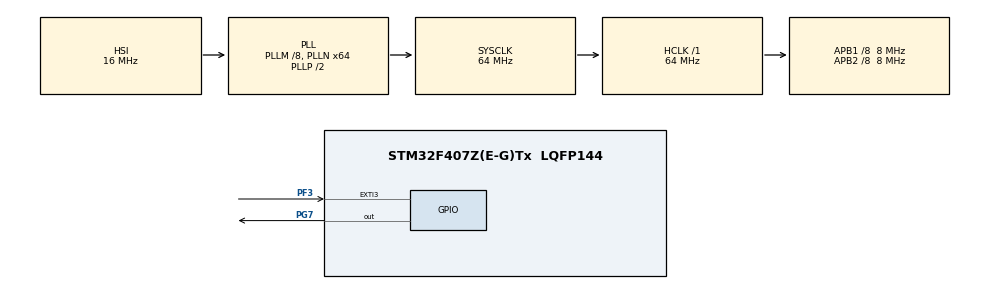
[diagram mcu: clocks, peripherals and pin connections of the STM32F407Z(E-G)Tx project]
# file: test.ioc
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Mcu.Family=STM32F4
Mcu.Name=STM32F407Z(E-G)Tx
Mcu.Package=LQFP144
NVIC.EXTI3_IRQn=true\:0\:0\:false\:false\:true\:true\:true\:true
NVIC.PriorityGroup=NVIC_PRIORITYGROUP_4
NVIC.TIM6_DAC_IRQn=true\:0\:0\:false\:false\:true\:true\:true\:true
PF3.Signal=GPXTI3
PG7.Signal=GPIO_Output
ProjectManager.HeapSize=0x200
ProjectManager.StackSize=0x400
ProjectManager.TargetToolchain=STM32CubeIDE
RCC.48MHZClocksFreq_Value=32000000
RCC.AHBFreq_Value=64000000
RCC.APB1CLKDivider=RCC_HCLK_DIV8
RCC.APB1Freq_Value=8000000
RCC.APB1TimFreq_Value=16000000
RCC.APB2CLKDivider=RCC_HCLK_DIV8
RCC.APB2Freq_Value=8000000
RCC.APB2TimFreq_Value=16000000
RCC.CortexFreq_Value=64000000
RCC.HCLKFreq_Value=64000000
RCC.HSE_VALUE=25000000
RCC.HSI_VALUE=16000000
RCC.LSE_VALUE=32768
RCC.PLLM=8
RCC.PLLN=64
RCC.SYSCLKFreq_VALUE=64000000
RCC.SYSCLKSource=RCC_SYSCLKSOURCE_PLLCLK
RCC.VCOOutputFreq_Value=128000000
TIM6.Period=65535
TIM6.Prescaler=15999
VP_TIM6_VS_ClockSourceINT.Mode=Enable_Timer
board=custom

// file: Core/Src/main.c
/* USER CODE BEGIN Header */
/**
  ******************************************************************************
  * @file           : main.c
  * @brief          : Main program body
  ******************************************************************************
  * @attention
  *
  * Copyright (c) 2023 STMicroelectronics.
  * All rights reserved.
  *
  * This software is licensed under terms that can be found in the LICENSE file
  * in the root directory of this software component.
  * If no LICENSE file comes with this software, it is provided AS-IS.
  *
  ******************************************************************************
  */
/* USER CODE END Header */
#include "main.h"

TIM_HandleTypeDef htim6;

/* USER CODE BEGIN PV */
int delay_reference=1000;
int delay;
int number_pressed=1;
int statuse;  // 0: idle 1: first  2: second
int t6;

/* USER CODE END PV */

void SystemClock_Config(void);
static void MX_GPIO_Init(void);
static void MX_TIM6_Init(void);

int main(void)
{
  /* USER CODE BEGIN 1 */
	delay=delay_reference;

	// External Interrupt ISR Handler CallBackFun

  /* USER CODE END 1 */

  /* MCU Configuration--------------------------------------------------------*/

  /* Reset of all peripherals, Initializes the Flash interface and the Systick. */
  HAL_Init();

  /* Configure the system clock */
  SystemClock_Config();

  /* Initialize all configured peripherals */
  MX_GPIO_Init();
  MX_TIM6_Init();

  /* Infinite loop */
  while (1)
  {

  }
}

void SystemClock_Config(void)
{
  RCC_OscInitTypeDef RCC_OscInitStruct = {0};
  RCC_ClkInitTypeDef RCC_ClkInitStruct = {0};

  /** Configure the main internal regulator output voltage
  */
  __HAL_RCC_PWR_CLK_ENABLE();
  __HAL_PWR_VOLTAGESCALING_CONFIG(PWR_REGULATOR_VOLTAGE_SCALE1);

  /** Initializes the RCC Oscillators according to the specified parameters
  * in the RCC_OscInitTypeDef structure.
  */
  RCC_OscInitStruct.OscillatorType = RCC_OSCILLATORTYPE_HSI;
  RCC_OscInitStruct.HSIState = RCC_HSI_ON;
  RCC_OscInitStruct.HSICalibrationValue = RCC_HSICALIBRATION_DEFAULT;
  RCC_OscInitStruct.PLL.PLLState = RCC_PLL_ON;
  RCC_OscInitStruct.PLL.PLLSource = RCC_PLLSOURCE_HSI;
  RCC_OscInitStruct.PLL.PLLM = 8;
  RCC_OscInitStruct.PLL.PLLN = 64;
  RCC_OscInitStruct.PLL.PLLP = RCC_PLLP_DIV2;
  RCC_OscInitStruct.PLL.PLLQ = 4;
  if (HAL_RCC_OscConfig(&RCC_OscInitStruct) != HAL_OK)
  {
    Error_Handler();
  }

  /** Initializes the CPU, AHB and APB buses clocks
  */
  RCC_ClkInitStruct.ClockType = RCC_CLOCKTYPE_HCLK|RCC_CLOCKTYPE_SYSCLK
                              |RCC_CLOCKTYPE_PCLK1|RCC_CLOCKTYPE_PCLK2;
  RCC_ClkInitStruct.SYSCLKSource = RCC_SYSCLKSOURCE_PLLCLK;
  RCC_ClkInitStruct.AHBCLKDivider = RCC_SYSCLK_DIV1;
  RCC_ClkInitStruct.APB1CLKDivider = RCC_HCLK_DIV8;
  RCC_ClkInitStruct.APB2CLKDivider = RCC_HCLK_DIV8;

  if (HAL_RCC_ClockConfig(&RCC_ClkInitStruct, FLASH_LATENCY_2) != HAL_OK)
  {
    Error_Handler();
  }
}

static void MX_TIM6_Init(void)
{

  TIM_MasterConfigTypeDef sMasterConfig = {0};

  htim6.Instance = TIM6;
  htim6.Init.Prescaler = 15999;
  htim6.Init.CounterMode = TIM_COUNTERMODE_UP;
  htim6.Init.Period = 65535;
  htim6.Init.AutoReloadPreload = TIM_AUTORELOAD_PRELOAD_DISABLE;
  if (HAL_TIM_Base_Init(&htim6) != HAL_OK)
  {
    Error_Handler();
  }
  sMasterConfig.MasterOutputTrigger = TIM_TRGO_RESET;
  sMasterConfig.MasterSlaveMode = TIM_MASTERSLAVEMODE_DISABLE;
  if (HAL_TIMEx_MasterConfigSynchronization(&htim6, &sMasterConfig) != HAL_OK)
  {
    Error_Handler();
  }

}

static void MX_GPIO_Init(void)
{
  GPIO_InitTypeDef GPIO_InitStruct = {0};

  /* GPIO Ports Clock Enable */
  __HAL_RCC_GPIOF_CLK_ENABLE();
  __HAL_RCC_GPIOG_CLK_ENABLE();

  /*Configure GPIO pin Output Level */
  HAL_GPIO_WritePin(GPIOG, GPIO_PIN_7, GPIO_PIN_RESET);

  /*Configure GPIO pin : PF3 */
  GPIO_InitStruct.Pin = GPIO_PIN_3;
  GPIO_InitStruct.Mode = GPIO_MODE_IT_RISING;
  GPIO_InitStruct.Pull = GPIO_NOPULL;
  HAL_GPIO_Init(GPIOF, &GPIO_InitStruct);

  /*Configure GPIO pin : PG7 */
  GPIO_InitStruct.Pin = GPIO_PIN_7;
  GPIO_InitStruct.Mode = GPIO_MODE_OUTPUT_PP;
  GPIO_InitStruct.Pull = GPIO_NOPULL;
  GPIO_InitStruct.Speed = GPIO_SPEED_FREQ_LOW;
  HAL_GPIO_Init(GPIOG, &GPIO_InitStruct);

  /* EXTI interrupt init*/
  HAL_NVIC_SetPriority(EXTI3_IRQn, 0, 0);
  HAL_NVIC_EnableIRQ(EXTI3_IRQn);

}

/* USER CODE BEGIN 4 */

void HAL_GPIO_EXTI_Callback(uint16_t pin)
{

	if(pin == GPIO_PIN_3){
		statuse+=1;

		 if(statuse==1){
			 __HAL_TIM_SET_COUNTER(&htim6, 0);
			 t6=0;
			 HAL_TIM_Base_Start(&htim6);

		 }else if(statuse==2){
			 HAL_TIM_Base_Stop(&htim6);
			 t6=__HAL_TIM_GetCounter(&htim6);
			 statuse=0;
		 }

	}
}

/* USER CODE END 4 */

void Error_Handler(void)
{
  __disable_irq();
  while (1)
  {
  }
}
